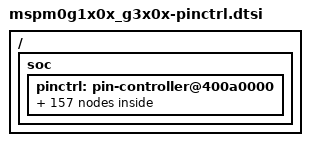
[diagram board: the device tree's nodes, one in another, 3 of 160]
#include <dt-bindings/pinctrl/mspm0-pinctrl.h>
#include "mspm0g-base-pinctrl.dtsi"

/{
	soc {
		pinctrl: pin-controller@400a0000 {
			/omit-if-no-ref/ timg8_ccp1_pa0: timg8_ccp1_pa0 {
				pinmux = <MSP_PINMUX(1, MSPM0_PIN_FUNCTION_6)>;
			};

			/omit-if-no-ref/ sysctl_fcc_in_pa0: sysctl_fcc_in_pa0 {
				pinmux = <MSP_PINMUX(1, MSPM0_PIN_FUNCTION_7)>;
				input-enable;
			};

			/omit-if-no-ref/ gpioa_pa28: gpioa_pa28 {
				pinmux = <MSP_PINMUX(3, MSPM0_PIN_FUNCTION_GPIO)>;
			};

			/omit-if-no-ref/ timg7_ccp0_pa28: timg7_ccp0_pa28 {
				pinmux = <MSP_PINMUX(3, MSPM0_PIN_FUNCTION_6)>;
			};

			/omit-if-no-ref/ tima1_ccp0_pa28: tima1_ccp0_pa28 {
				pinmux = <MSP_PINMUX(3, MSPM0_PIN_FUNCTION_7)>;
			};

			/omit-if-no-ref/ uart2_rts_pa29: uart2_rts_pa29 {
				pinmux = <MSP_PINMUX(4, MSPM0_PIN_FUNCTION_3)>;
			};

			/omit-if-no-ref/ timg6_ccp0_pa29: timg6_ccp0_pa29 {
				pinmux = <MSP_PINMUX(4, MSPM0_PIN_FUNCTION_5)>;
			};

			/omit-if-no-ref/ uart2_cts_pa30: uart2_cts_pa30 {
				pinmux = <MSP_PINMUX(5, MSPM0_PIN_FUNCTION_3)>;
				input-enable;
			};

			/omit-if-no-ref/ timg6_ccp1_pa30: timg6_ccp1_pa30 {
				pinmux = <MSP_PINMUX(5, MSPM0_PIN_FUNCTION_5)>;
			};

			/omit-if-no-ref/ timg7_ccp1_pa31: timg7_ccp1_pa31 {
				pinmux = <MSP_PINMUX(6, MSPM0_PIN_FUNCTION_7)>;
			};

			/omit-if-no-ref/ tima1_ccp1_pa31: tima1_ccp1_pa31 {
				pinmux = <MSP_PINMUX(6, MSPM0_PIN_FUNCTION_8)>;
			};

			/omit-if-no-ref/ uart2_cts_pa3: uart2_cts_pa3 {
				pinmux = <MSP_PINMUX(8, MSPM0_PIN_FUNCTION_4)>;
				input-enable;
			};

			/omit-if-no-ref/ tima0_ccp2_pa3: tima0_ccp2_pa3 {
				pinmux = <MSP_PINMUX(8, MSPM0_PIN_FUNCTION_5)>;
			};

			/omit-if-no-ref/ comp1_out_pa3: comp1_out_pa3 {
				pinmux = <MSP_PINMUX(8, MSPM0_PIN_FUNCTION_6)>;
			};

			/omit-if-no-ref/ timg7_ccp0_pa3: timg7_ccp0_pa3 {
				pinmux = <MSP_PINMUX(8, MSPM0_PIN_FUNCTION_7)>;
			};

			/omit-if-no-ref/ tima0_ccp1_pa3: tima0_ccp1_pa3 {
				pinmux = <MSP_PINMUX(8, MSPM0_PIN_FUNCTION_8)>;
			};

			/omit-if-no-ref/ i2c1_sda_pa3: i2c1_sda_pa3 {
				pinmux = <MSP_PINMUX(8, MSPM0_PIN_FUNCTION_9)>;
				input-enable;
				drive-open-drain;
				bias-disable;
			};

			/omit-if-no-ref/ uart2_rts_pa4: uart2_rts_pa4 {
				pinmux = <MSP_PINMUX(9, MSPM0_PIN_FUNCTION_4)>;
			};

			/omit-if-no-ref/ tima0_ccp3_pa4: tima0_ccp3_pa4 {
				pinmux = <MSP_PINMUX(9, MSPM0_PIN_FUNCTION_5)>;
			};

			/omit-if-no-ref/ timg7_ccp1_pa4: timg7_ccp1_pa4 {
				pinmux = <MSP_PINMUX(9, MSPM0_PIN_FUNCTION_7)>;
			};

			/omit-if-no-ref/ tima0_ccp1_cmpl_pa4: tima0_ccp1_cmpl_pa4 {
				pinmux = <MSP_PINMUX(9, MSPM0_PIN_FUNCTION_8)>;
			};

			/omit-if-no-ref/ i2c1_scl_pa4: i2c1_scl_pa4 {
				pinmux = <MSP_PINMUX(9, MSPM0_PIN_FUNCTION_9)>;
				input-enable;
				drive-open-drain;
				bias-disable;
			};

			/omit-if-no-ref/ tima_fault1_pa5: tima_fault1_pa5 {
				pinmux = <MSP_PINMUX(10, MSPM0_PIN_FUNCTION_4)>;
			};

			/omit-if-no-ref/ timg6_ccp0_pa5: timg6_ccp0_pa5 {
				pinmux = <MSP_PINMUX(10, MSPM0_PIN_FUNCTION_6)>;
			};

			/omit-if-no-ref/ sysctl_fcc_in_pa5: sysctl_fcc_in_pa5 {
				pinmux = <MSP_PINMUX(10, MSPM0_PIN_FUNCTION_7)>;
				input-enable;
			};

			/omit-if-no-ref/ tima_fault0_pa6: tima_fault0_pa6 {
				pinmux = <MSP_PINMUX(11, MSPM0_PIN_FUNCTION_4)>;
			};

			/omit-if-no-ref/ tima0_ccp2_cmpl_pa6: tima0_ccp2_cmpl_pa6 {
				pinmux = <MSP_PINMUX(11, MSPM0_PIN_FUNCTION_8)>;
			};

			/omit-if-no-ref/ spi1_cs2_poci_pb02: spi1_cs2_poci_pb02 {
				pinmux = <MSP_PINMUX(12, MSPM0_PIN_FUNCTION_3)>;
				input-enable;
			};

			/omit-if-no-ref/ tima1_ccp0_pb0: tima1_ccp0_pb0 {
				pinmux = <MSP_PINMUX(12, MSPM0_PIN_FUNCTION_4)>;
			};

			/omit-if-no-ref/ spi1_cs3_cd_poci3_pb1: spi1_cs3_cd_poci3_pb1 {
				pinmux = <MSP_PINMUX(13, MSPM0_PIN_FUNCTION_3)>;
				input-enable;
			};

			/omit-if-no-ref/ tima1_ccp1_pb1: tima1_ccp1_pb1 {
				pinmux = <MSP_PINMUX(13, MSPM0_PIN_FUNCTION_4)>;
			};

			/omit-if-no-ref/ uart2_cts_pb2: uart2_cts_pb2 {
				pinmux = <MSP_PINMUX(15, MSPM0_PIN_FUNCTION_3)>;
				input-enable;
			};

			/omit-if-no-ref/ timg6_ccp0_pb2: timg6_ccp0_pb2 {
				pinmux = <MSP_PINMUX(15, MSPM0_PIN_FUNCTION_7)>;
			};

			/omit-if-no-ref/ tima1_ccp0_pb2: tima1_ccp0_pb2 {
				pinmux = <MSP_PINMUX(15, MSPM0_PIN_FUNCTION_8)>;
			};

			/omit-if-no-ref/ uart2_rts_pb3: uart2_rts_pb3 {
				pinmux = <MSP_PINMUX(16, MSPM0_PIN_FUNCTION_3)>;
			};

			/omit-if-no-ref/ timg6_ccp1_pb3: timg6_ccp1_pb3 {
				pinmux = <MSP_PINMUX(16, MSPM0_PIN_FUNCTION_7)>;
			};

			/omit-if-no-ref/ tima1_ccp1_pb3: tima1_ccp1_pb3 {
				pinmux = <MSP_PINMUX(16, MSPM0_PIN_FUNCTION_8)>;
			};

			/omit-if-no-ref/ tima1_ccp0_pb4: tima1_ccp0_pb4 {
				pinmux = <MSP_PINMUX(17, MSPM0_PIN_FUNCTION_4)>;
			};

			/omit-if-no-ref/ tima1_ccp0_cmpl_pb4: tima1_ccp0_cmpl_pb4 {
				pinmux = <MSP_PINMUX(17, MSPM0_PIN_FUNCTION_6)>;
			};

			/omit-if-no-ref/ tima1_ccp1_pb5: tima1_ccp1_pb5 {
				pinmux = <MSP_PINMUX(18, MSPM0_PIN_FUNCTION_4)>;
			};

			/omit-if-no-ref/ tima1_ccp1_cmpl_pb5: tima1_ccp1_cmpl_pb5 {
				pinmux = <MSP_PINMUX(18, MSPM0_PIN_FUNCTION_6)>;
			};

			/omit-if-no-ref/ uart0_rts_pa8: uart0_rts_pa8 {
				pinmux = <MSP_PINMUX(19, MSPM0_PIN_FUNCTION_4)>;
			};

			/omit-if-no-ref/ tima1_ccp0_cmpl_pa8: tima1_ccp0_cmpl_pa8 {
				pinmux = <MSP_PINMUX(19, MSPM0_PIN_FUNCTION_6)>;
			};

			/omit-if-no-ref/ uart0_cts_pa9: uart0_cts_pa9 {
				pinmux = <MSP_PINMUX(20, MSPM0_PIN_FUNCTION_4)>;
				input-enable;
			};

			/omit-if-no-ref/ tima0_ccp1_pa9: tima0_ccp1_pa9 {
				pinmux = <MSP_PINMUX(20, MSPM0_PIN_FUNCTION_5)>;
			};

			/omit-if-no-ref/ rtc_rtc_out_pa9: rtc_rtc_out_pa9 {
				pinmux = <MSP_PINMUX(20, MSPM0_PIN_FUNCTION_6)>;
			};

			/omit-if-no-ref/ tima0_ccp0_cmpl_pa9: tima0_ccp0_cmpl_pa9 {
				pinmux = <MSP_PINMUX(20, MSPM0_PIN_FUNCTION_7)>;
			};

			/omit-if-no-ref/ tima1_ccp1_cmpl_pa9: tima1_ccp1_cmpl_pa9 {
				pinmux = <MSP_PINMUX(20, MSPM0_PIN_FUNCTION_8)>;
			};

			/omit-if-no-ref/ sysctl_clk_out_pa9: sysctl_clk_out_pa9 {
				pinmux = <MSP_PINMUX(20, MSPM0_PIN_FUNCTION_9)>;
			};

			/omit-if-no-ref/ tima1_ccp0_pa10: tima1_ccp0_pa10 {
				pinmux = <MSP_PINMUX(21, MSPM0_PIN_FUNCTION_5)>;
			};

			/omit-if-no-ref/ timg12_ccp0_pa10: timg12_ccp0_pa10 {
				pinmux = <MSP_PINMUX(21, MSPM0_PIN_FUNCTION_6)>;
			};

			/omit-if-no-ref/ tima0_ccp2_pa10: tima0_ccp2_pa10 {
				pinmux = <MSP_PINMUX(21, MSPM0_PIN_FUNCTION_7)>;
			};

			/omit-if-no-ref/ sysctl_clk_out_pa10: sysctl_clk_out_pa10 {
				pinmux = <MSP_PINMUX(21, MSPM0_PIN_FUNCTION_9)>;
			};

			/omit-if-no-ref/ tima1_ccp1_pa11: tima1_ccp1_pa11 {
				pinmux = <MSP_PINMUX(22, MSPM0_PIN_FUNCTION_5)>;
			};

			/omit-if-no-ref/ tima0_ccp2_cmpl_pa11: tima0_ccp2_cmpl_pa11 {
				pinmux = <MSP_PINMUX(22, MSPM0_PIN_FUNCTION_7)>;
			};

			/omit-if-no-ref/ spi0_cs1_poci1_pb6: spi0_cs1_poci1_pb6 {
				pinmux = <MSP_PINMUX(23, MSPM0_PIN_FUNCTION_4)>;
				input-enable;
			};

			/omit-if-no-ref/ uart2_cts_pb6: uart2_cts_pb6 {
				pinmux = <MSP_PINMUX(23, MSPM0_PIN_FUNCTION_6)>;
				input-enable;
			};

			/omit-if-no-ref/ timg6_ccp0_pb6: timg6_ccp0_pb6 {
				pinmux = <MSP_PINMUX(23, MSPM0_PIN_FUNCTION_7)>;
			};

			/omit-if-no-ref/ tima1_ccp0_cmpl_pb6: tima1_ccp0_cmpl_pb6 {
				pinmux = <MSP_PINMUX(23, MSPM0_PIN_FUNCTION_8)>;
			};

			/omit-if-no-ref/ spi0_cs2_poci2_pb7: spi0_cs2_poci2_pb7 {
				pinmux = <MSP_PINMUX(24, MSPM0_PIN_FUNCTION_4)>;
				input-enable;
			};

			/omit-if-no-ref/ uart2_rts_pb7: uart2_rts_pb7 {
				pinmux = <MSP_PINMUX(24, MSPM0_PIN_FUNCTION_6)>;
			};

			/omit-if-no-ref/ timg6_ccp1_pb7: timg6_ccp1_pb7 {
				pinmux = <MSP_PINMUX(24, MSPM0_PIN_FUNCTION_7)>;
			};

			/omit-if-no-ref/ tima1_ccp1_cmpl_pb7: tima1_ccp1_cmpl_pb7 {
				pinmux = <MSP_PINMUX(24, MSPM0_PIN_FUNCTION_8)>;
			};

			/omit-if-no-ref/ tima0_ccp0_pb8: tima0_ccp0_pb8 {
				pinmux = <MSP_PINMUX(25, MSPM0_PIN_FUNCTION_4)>;
			};

			/omit-if-no-ref/ comp1_out_pb8: comp1_out_pb8 {
				pinmux = <MSP_PINMUX(25, MSPM0_PIN_FUNCTION_5)>;
			};

			/omit-if-no-ref/ tima0_ccp1_pb9: tima0_ccp1_pb9 {
				pinmux = <MSP_PINMUX(26, MSPM0_PIN_FUNCTION_4)>;
			};

			/omit-if-no-ref/ comp1_out_pb10: comp1_out_pb10 {
				pinmux = <MSP_PINMUX(27, MSPM0_PIN_FUNCTION_4)>;
			};

			/omit-if-no-ref/ timg6_ccp0_pb10: timg6_ccp0_pb10 {
				pinmux = <MSP_PINMUX(27, MSPM0_PIN_FUNCTION_5)>;
			};

			/omit-if-no-ref/ timg6_ccp1_pb11: timg6_ccp1_pb11 {
				pinmux = <MSP_PINMUX(28, MSPM0_PIN_FUNCTION_5)>;
			};

			/omit-if-no-ref/ spi1_cs3_cd_poci3_pb14: spi1_cs3_cd_poci3_pb14 {
				pinmux = <MSP_PINMUX(31, MSPM0_PIN_FUNCTION_2)>;
				input-enable;
			};

			/omit-if-no-ref/ spi0_cs3_cd_poci3_pb14: spi0_cs3_cd_poci3_pb14 {
				pinmux = <MSP_PINMUX(31, MSPM0_PIN_FUNCTION_4)>;
				input-enable;
			};

			/omit-if-no-ref/ timg12_ccp1_pb14: timg12_ccp1_pb14 {
				pinmux = <MSP_PINMUX(31, MSPM0_PIN_FUNCTION_5)>;
			};

			/omit-if-no-ref/ tima0_ccp0_pb14: tima0_ccp0_pb14 {
				pinmux = <MSP_PINMUX(31, MSPM0_PIN_FUNCTION_7)>;
			};

			/omit-if-no-ref/ uart2_tx_pb15: uart2_tx_pb15 {
				pinmux = <MSP_PINMUX(32, MSPM0_PIN_FUNCTION_2)>;
			};

			/omit-if-no-ref/ timg7_ccp0_pb15: timg7_ccp0_pb15 {
				pinmux = <MSP_PINMUX(32, MSPM0_PIN_FUNCTION_6)>;
			};

			/omit-if-no-ref/ uart2_rx_pb16: uart2_rx_pb16 {
				pinmux = <MSP_PINMUX(33, MSPM0_PIN_FUNCTION_2)>;
				input-enable;
			};

			/omit-if-no-ref/ timg7_ccp1_pb16: timg7_ccp1_pb16 {
				pinmux = <MSP_PINMUX(33, MSPM0_PIN_FUNCTION_6)>;
			};

			/omit-if-no-ref/ timg0_ccp0_pa12: timg0_ccp0_pa12 {
				pinmux = <MSP_PINMUX(34, MSPM0_PIN_FUNCTION_4)>;
			};

			/omit-if-no-ref/ canfd0_cantx_pa12: canfd0_cantx_pa12 {
				pinmux = <MSP_PINMUX(34, MSPM0_PIN_FUNCTION_5)>;
			};

			/omit-if-no-ref/ tima0_ccp3_pa12: tima0_ccp3_pa12 {
				pinmux = <MSP_PINMUX(34, MSPM0_PIN_FUNCTION_6)>;
			};

			/omit-if-no-ref/ sysctl_fcc_in_pa12: sysctl_fcc_in_pa12 {
				pinmux = <MSP_PINMUX(34, MSPM0_PIN_FUNCTION_7)>;
				input-enable;
			};

			/omit-if-no-ref/ timg0_ccp1_pa13: timg0_ccp1_pa13 {
				pinmux = <MSP_PINMUX(35, MSPM0_PIN_FUNCTION_5)>;
			};

			/omit-if-no-ref/ canfd0_canrx_pa13: canfd0_canrx_pa13 {
				pinmux = <MSP_PINMUX(35, MSPM0_PIN_FUNCTION_6)>;
				input-enable;
			};

			/omit-if-no-ref/ tima0_ccp3_cmpl_pa13: tima0_ccp3_cmpl_pa13 {
				pinmux = <MSP_PINMUX(35, MSPM0_PIN_FUNCTION_7)>;
			};

			/omit-if-no-ref/ tima1_ccp0_pa15: tima1_ccp0_pa15 {
				pinmux = <MSP_PINMUX(37, MSPM0_PIN_FUNCTION_5)>;
			};

			/omit-if-no-ref/ timg8_idx_pa15: timg8_idx_pa15 {
				pinmux = <MSP_PINMUX(37, MSPM0_PIN_FUNCTION_6)>;
			};

			/omit-if-no-ref/ tima1_ccp0_cmpl_pa15: tima1_ccp0_cmpl_pa15 {
				pinmux = <MSP_PINMUX(37, MSPM0_PIN_FUNCTION_7)>;
			};

			/omit-if-no-ref/ tima0_ccp2_pa15: tima0_ccp2_pa15 {
				pinmux = <MSP_PINMUX(37, MSPM0_PIN_FUNCTION_8)>;
			};

			/omit-if-no-ref/ comp2_out_pa16: comp2_out_pa16 {
				pinmux = <MSP_PINMUX(38, MSPM0_PIN_FUNCTION_2)>;
			};

			/omit-if-no-ref/ tima1_ccp1_pa16: tima1_ccp1_pa16 {
				pinmux = <MSP_PINMUX(38, MSPM0_PIN_FUNCTION_5)>;
			};

			/omit-if-no-ref/ tima1_ccp1_cmpl_pa16: tima1_ccp1_cmpl_pa16 {
				pinmux = <MSP_PINMUX(38, MSPM0_PIN_FUNCTION_6)>;
			};

			/omit-if-no-ref/ tima0_ccp2_cmpl_pa16: tima0_ccp2_cmpl_pa16 {
				pinmux = <MSP_PINMUX(38, MSPM0_PIN_FUNCTION_7)>;
			};

			/omit-if-no-ref/ sysctl_fcc_in_pa16: sysctl_fcc_in_pa16 {
				pinmux = <MSP_PINMUX(38, MSPM0_PIN_FUNCTION_8)>;
				input-enable;
			};

			/omit-if-no-ref/ timg7_ccp0_pa17: timg7_ccp0_pa17 {
				pinmux = <MSP_PINMUX(39, MSPM0_PIN_FUNCTION_6)>;
			};

			/omit-if-no-ref/ tima1_ccp0_pa17: tima1_ccp0_pa17 {
				pinmux = <MSP_PINMUX(39, MSPM0_PIN_FUNCTION_7)>;
			};

			/omit-if-no-ref/ timg7_ccp1_pa18: timg7_ccp1_pa18 {
				pinmux = <MSP_PINMUX(40, MSPM0_PIN_FUNCTION_6)>;
			};

			/omit-if-no-ref/ tima1_ccp1_pa18: tima1_ccp1_pa18 {
				pinmux = <MSP_PINMUX(40, MSPM0_PIN_FUNCTION_7)>;
			};

			/omit-if-no-ref/ debugss_sw_pa19: debugss_sw_pa19 {
				pinmux = <MSP_PINMUX(41, MSPM0_PIN_FUNCTION_2)>;
			};

			/omit-if-no-ref/ uart2_tx_pb17: uart2_tx_pb17 {
				pinmux = <MSP_PINMUX(43, MSPM0_PIN_FUNCTION_2)>;
			};

			/omit-if-no-ref/ spi1_cs1_poci1_pb17: spi1_cs1_poci1_pb17 {
				pinmux = <MSP_PINMUX(43, MSPM0_PIN_FUNCTION_4)>;
				input-enable;
			};

			/omit-if-no-ref/ tima1_ccp0_pb17: tima1_ccp0_pb17 {
				pinmux = <MSP_PINMUX(43, MSPM0_PIN_FUNCTION_5)>;
			};

			/omit-if-no-ref/ tima0_ccp2_pb17: tima0_ccp2_pb17 {
				pinmux = <MSP_PINMUX(43, MSPM0_PIN_FUNCTION_6)>;
			};

			/omit-if-no-ref/ uart2_rx_pb18: uart2_rx_pb18 {
				pinmux = <MSP_PINMUX(44, MSPM0_PIN_FUNCTION_2)>;
				input-enable;
			};

			/omit-if-no-ref/ spi1_cs2_poci2_pb18: spi1_cs2_poci2_pb18 {
				pinmux = <MSP_PINMUX(44, MSPM0_PIN_FUNCTION_4)>;
				input-enable;
			};

			/omit-if-no-ref/ tima1_ccp1_pb18: tima1_ccp1_pb18 {
				pinmux = <MSP_PINMUX(44, MSPM0_PIN_FUNCTION_5)>;
			};

			/omit-if-no-ref/ tima0_ccp2_cmpl_pb18: tima0_ccp2_cmpl_pb18 {
				pinmux = <MSP_PINMUX(44, MSPM0_PIN_FUNCTION_6)>;
			};

			/omit-if-no-ref/ comp2_out_pb19: comp2_out_pb19 {
				pinmux = <MSP_PINMUX(45, MSPM0_PIN_FUNCTION_2)>;
			};

			/omit-if-no-ref/ timg7_ccp1_pb19: timg7_ccp1_pb19 {
				pinmux = <MSP_PINMUX(45, MSPM0_PIN_FUNCTION_6)>;
			};

			/omit-if-no-ref/ uart2_tx_pa21: uart2_tx_pa21 {
				pinmux = <MSP_PINMUX(46, MSPM0_PIN_FUNCTION_2)>;
			};

			/omit-if-no-ref/ timg8_ccp0_pa21: timg8_ccp0_pa21 {
				pinmux = <MSP_PINMUX(46, MSPM0_PIN_FUNCTION_3)>;
			};

			/omit-if-no-ref/ timg6_ccp0_pa21: timg6_ccp0_pa21 {
				pinmux = <MSP_PINMUX(46, MSPM0_PIN_FUNCTION_6)>;
			};

			/omit-if-no-ref/ uart2_rx_pa22: uart2_rx_pa22 {
				pinmux = <MSP_PINMUX(47, MSPM0_PIN_FUNCTION_2)>;
				input-enable;
			};

			/omit-if-no-ref/ timg8_ccp1_pa22: timg8_ccp1_pa22 {
				pinmux = <MSP_PINMUX(47, MSPM0_PIN_FUNCTION_3)>;
			};

			/omit-if-no-ref/ tima0_ccp1_pa22: tima0_ccp1_pa22 {
				pinmux = <MSP_PINMUX(47, MSPM0_PIN_FUNCTION_5)>;
			};

			/omit-if-no-ref/ sysctl_clk_out_pa22: sysctl_clk_out_pa22 {
				pinmux = <MSP_PINMUX(47, MSPM0_PIN_FUNCTION_6)>;
			};

			/omit-if-no-ref/ tima0_ccp0_cmpl_pa22: tima0_ccp0_cmpl_pa22 {
				pinmux = <MSP_PINMUX(47, MSPM0_PIN_FUNCTION_7)>;
			};

			/omit-if-no-ref/ timg6_ccp1_pa22: timg6_ccp1_pa22 {
				pinmux = <MSP_PINMUX(47, MSPM0_PIN_FUNCTION_8)>;
			};

			/omit-if-no-ref/ tima0_ccp2_pb20: tima0_ccp2_pb20 {
				pinmux = <MSP_PINMUX(48, MSPM0_PIN_FUNCTION_4)>;
			};

			/omit-if-no-ref/ timg12_ccp0_pb20: timg12_ccp0_pb20 {
				pinmux = <MSP_PINMUX(48, MSPM0_PIN_FUNCTION_5)>;
			};

			/omit-if-no-ref/ tima1_ccp1_cmpl_pb20: tima1_ccp1_cmpl_pb20 {
				pinmux = <MSP_PINMUX(48, MSPM0_PIN_FUNCTION_8)>;
			};

			/omit-if-no-ref/ spi1_poci_pb21: spi1_poci_pb21 {
				pinmux = <MSP_PINMUX(49, MSPM0_PIN_FUNCTION_2)>;
				input-enable;
			};

			/omit-if-no-ref/ timg8_ccp0_pb21: timg8_ccp0_pb21 {
				pinmux = <MSP_PINMUX(49, MSPM0_PIN_FUNCTION_3)>;
			};

			/omit-if-no-ref/ spi1_pico_pb22: spi1_pico_pb22 {
				pinmux = <MSP_PINMUX(50, MSPM0_PIN_FUNCTION_2)>;
			};

			/omit-if-no-ref/ timg8_ccp1_pb22: timg8_ccp1_pb22 {
				pinmux = <MSP_PINMUX(50, MSPM0_PIN_FUNCTION_3)>;
			};

			/omit-if-no-ref/ spi1_sclk_pb23: spi1_sclk_pb23 {
				pinmux = <MSP_PINMUX(51, MSPM0_PIN_FUNCTION_2)>;
			};

			/omit-if-no-ref/ comp0_out_pb23: comp0_out_pb23 {
				pinmux = <MSP_PINMUX(51, MSPM0_PIN_FUNCTION_3)>;
			};

			/omit-if-no-ref/ spi0_cs3_cd_poci3_pb24: spi0_cs3_cd_poci3_pb24 {
				pinmux = <MSP_PINMUX(52, MSPM0_PIN_FUNCTION_2)>;
				input-enable;
			};

			/omit-if-no-ref/ tima0_ccp3_pb24: tima0_ccp3_pb24 {
				pinmux = <MSP_PINMUX(52, MSPM0_PIN_FUNCTION_4)>;
			};

			/omit-if-no-ref/ timg12_ccp1_pb24: timg12_ccp1_pb24 {
				pinmux = <MSP_PINMUX(52, MSPM0_PIN_FUNCTION_5)>;
			};

			/omit-if-no-ref/ tima1_ccp0_cmpl_pb24: tima1_ccp0_cmpl_pb24 {
				pinmux = <MSP_PINMUX(52, MSPM0_PIN_FUNCTION_7)>;
			};

			/omit-if-no-ref/ uart2_tx_pa23: uart2_tx_pa23 {
				pinmux = <MSP_PINMUX(53, MSPM0_PIN_FUNCTION_2)>;
			};

			/omit-if-no-ref/ spi0_cs3_cd_poci3_pa23: spi0_cs3_cd_poci3_pa23 {
				pinmux = <MSP_PINMUX(53, MSPM0_PIN_FUNCTION_3)>;
				input-enable;
			};

			/omit-if-no-ref/ tima0_ccp3_pa23: tima0_ccp3_pa23 {
				pinmux = <MSP_PINMUX(53, MSPM0_PIN_FUNCTION_4)>;
			};

			/omit-if-no-ref/ timg0_ccp0_pa23: timg0_ccp0_pa23 {
				pinmux = <MSP_PINMUX(53, MSPM0_PIN_FUNCTION_5)>;
			};

			/omit-if-no-ref/ uart3_cts_pa23: uart3_cts_pa23 {
				pinmux = <MSP_PINMUX(53, MSPM0_PIN_FUNCTION_6)>;
				input-enable;
			};

			/omit-if-no-ref/ timg7_ccp0_pa23: timg7_ccp0_pa23 {
				pinmux = <MSP_PINMUX(53, MSPM0_PIN_FUNCTION_7)>;
			};

			/omit-if-no-ref/ timg8_ccp0_pa23: timg8_ccp0_pa23 {
				pinmux = <MSP_PINMUX(53, MSPM0_PIN_FUNCTION_8)>;
			};

			/omit-if-no-ref/ uart2_rx_pa24: uart2_rx_pa24 {
				pinmux = <MSP_PINMUX(54, MSPM0_PIN_FUNCTION_2)>;
				input-enable;
			};

			/omit-if-no-ref/ tima0_ccp3_cmpl_pa24: tima0_ccp3_cmpl_pa24 {
				pinmux = <MSP_PINMUX(54, MSPM0_PIN_FUNCTION_4)>;
			};

			/omit-if-no-ref/ timg0_ccp1_pa24: timg0_ccp1_pa24 {
				pinmux = <MSP_PINMUX(54, MSPM0_PIN_FUNCTION_5)>;
			};

			/omit-if-no-ref/ uart3_rts_pa24: uart3_rts_pa24 {
				pinmux = <MSP_PINMUX(54, MSPM0_PIN_FUNCTION_6)>;
			};

			/omit-if-no-ref/ timg7_ccp1_pa24: timg7_ccp1_pa24 {
				pinmux = <MSP_PINMUX(54, MSPM0_PIN_FUNCTION_7)>;
			};

			/omit-if-no-ref/ tima1_ccp1_pa24: tima1_ccp1_pa24 {
				pinmux = <MSP_PINMUX(54, MSPM0_PIN_FUNCTION_8)>;
			};

			/omit-if-no-ref/ spi1_cs3_cd_poci3_pa25: spi1_cs3_cd_poci3_pa25 {
				pinmux = <MSP_PINMUX(55, MSPM0_PIN_FUNCTION_3)>;
				input-enable;
			};

			/omit-if-no-ref/ tima_fault2_pb25: tima_fault2_pb25 {
				pinmux = <MSP_PINMUX(56, MSPM0_PIN_FUNCTION_4)>;
			};

			/omit-if-no-ref/ tima0_ccp3_pb26: tima0_ccp3_pb26 {
				pinmux = <MSP_PINMUX(57, MSPM0_PIN_FUNCTION_4)>;
			};

			/omit-if-no-ref/ timg6_ccp0_pb26: timg6_ccp0_pb26 {
				pinmux = <MSP_PINMUX(57, MSPM0_PIN_FUNCTION_5)>;
			};

			/omit-if-no-ref/ tima1_ccp0_pb26: tima1_ccp0_pb26 {
				pinmux = <MSP_PINMUX(57, MSPM0_PIN_FUNCTION_6)>;
			};

			/omit-if-no-ref/ comp2_out_pb27: comp2_out_pb27 {
				pinmux = <MSP_PINMUX(58, MSPM0_PIN_FUNCTION_2)>;
			};

			/omit-if-no-ref/ tima0_ccp3_cmpl_pb27: tima0_ccp3_cmpl_pb27 {
				pinmux = <MSP_PINMUX(58, MSPM0_PIN_FUNCTION_4)>;
			};

			/omit-if-no-ref/ timg6_ccp1_pb27: timg6_ccp1_pb27 {
				pinmux = <MSP_PINMUX(58, MSPM0_PIN_FUNCTION_5)>;
			};

			/omit-if-no-ref/ tima1_ccp1_pb27: tima1_ccp1_pb27 {
				pinmux = <MSP_PINMUX(58, MSPM0_PIN_FUNCTION_6)>;
			};

			/omit-if-no-ref/ canfd0_cantx_pa26: canfd0_cantx_pa26 {
				pinmux = <MSP_PINMUX(59, MSPM0_PIN_FUNCTION_6)>;
			};

			/omit-if-no-ref/ timg7_ccp0_pa26: timg7_ccp0_pa26 {
				pinmux = <MSP_PINMUX(59, MSPM0_PIN_FUNCTION_7)>;
			};

			/omit-if-no-ref/ rtc_rtc_out_pa27: rtc_rtc_out_pa27 {
				pinmux = <MSP_PINMUX(60, MSPM0_PIN_FUNCTION_2)>;
			};

			/omit-if-no-ref/ canfd0_canrx_pa27: canfd0_canrx_pa27 {
				pinmux = <MSP_PINMUX(60, MSPM0_PIN_FUNCTION_6)>;
				input-enable;
			};

			/omit-if-no-ref/ timg7_ccp1_pa27: timg7_ccp1_pa27 {
				pinmux = <MSP_PINMUX(60, MSPM0_PIN_FUNCTION_7)>;
			};

		};
	};
};
